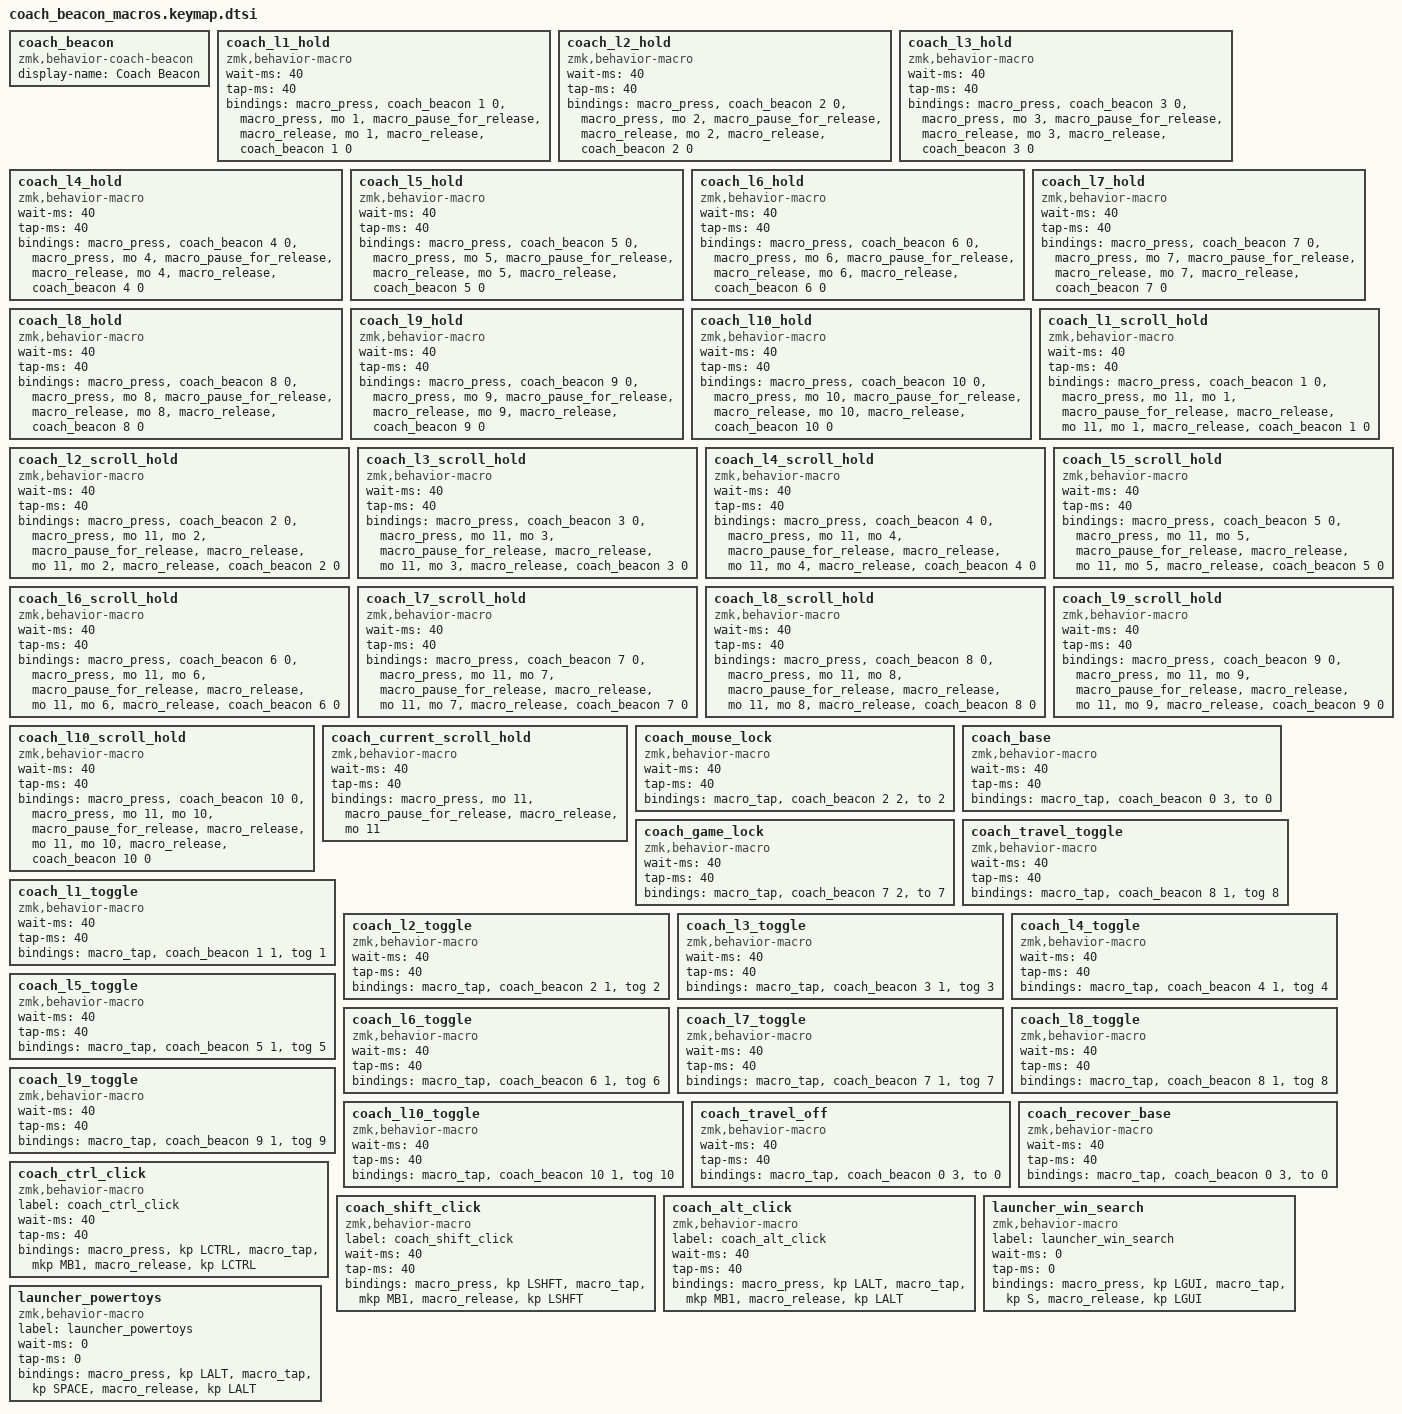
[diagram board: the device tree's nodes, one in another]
/* Coach state is sent over the private GATT service, never as keyboard input. */

coach_beacon: coach_beacon {
    compatible = "zmk,behavior-coach-beacon";
    #binding-cells = <2>;
    display-name = "Coach Beacon";
};

coach_l1_hold: coach_l1_hold {
            compatible = "zmk,behavior-macro";
            #binding-cells = <0>;
            wait-ms = <40>;
            tap-ms = <40>;
            bindings =
                <&macro_press &coach_beacon 1 0>,
                <&macro_press &mo 1>,
                <&macro_pause_for_release>,
                <&macro_release &mo 1>,
                <&macro_release &coach_beacon 1 0>;
        };

        coach_l2_hold: coach_l2_hold {
            compatible = "zmk,behavior-macro";
            #binding-cells = <0>;
            wait-ms = <40>;
            tap-ms = <40>;
            bindings =
                <&macro_press &coach_beacon 2 0>,
                <&macro_press &mo 2>,
                <&macro_pause_for_release>,
                <&macro_release &mo 2>,
                <&macro_release &coach_beacon 2 0>;
        };

        coach_l3_hold: coach_l3_hold {
            compatible = "zmk,behavior-macro";
            #binding-cells = <0>;
            wait-ms = <40>;
            tap-ms = <40>;
            bindings =
                <&macro_press &coach_beacon 3 0>,
                <&macro_press &mo 3>,
                <&macro_pause_for_release>,
                <&macro_release &mo 3>,
                <&macro_release &coach_beacon 3 0>;
        };

        coach_l4_hold: coach_l4_hold {
            compatible = "zmk,behavior-macro";
            #binding-cells = <0>;
            wait-ms = <40>;
            tap-ms = <40>;
            bindings =
                <&macro_press &coach_beacon 4 0>,
                <&macro_press &mo 4>,
                <&macro_pause_for_release>,
                <&macro_release &mo 4>,
                <&macro_release &coach_beacon 4 0>;
        };

        coach_l5_hold: coach_l5_hold {
            compatible = "zmk,behavior-macro";
            #binding-cells = <0>;
            wait-ms = <40>;
            tap-ms = <40>;
            bindings =
                <&macro_press &coach_beacon 5 0>,
                <&macro_press &mo 5>,
                <&macro_pause_for_release>,
                <&macro_release &mo 5>,
                <&macro_release &coach_beacon 5 0>;
        };

        coach_l6_hold: coach_l6_hold {
            compatible = "zmk,behavior-macro";
            #binding-cells = <0>;
            wait-ms = <40>;
            tap-ms = <40>;
            bindings =
                <&macro_press &coach_beacon 6 0>,
                <&macro_press &mo 6>,
                <&macro_pause_for_release>,
                <&macro_release &mo 6>,
                <&macro_release &coach_beacon 6 0>;
        };

        coach_l7_hold: coach_l7_hold {
            compatible = "zmk,behavior-macro";
            #binding-cells = <0>;
            wait-ms = <40>;
            tap-ms = <40>;
            bindings =
                <&macro_press &coach_beacon 7 0>,
                <&macro_press &mo 7>,
                <&macro_pause_for_release>,
                <&macro_release &mo 7>,
                <&macro_release &coach_beacon 7 0>;
        };

        coach_l8_hold: coach_l8_hold {
            compatible = "zmk,behavior-macro";
            #binding-cells = <0>;
            wait-ms = <40>;
            tap-ms = <40>;
            bindings =
                <&macro_press &coach_beacon 8 0>,
                <&macro_press &mo 8>,
                <&macro_pause_for_release>,
                <&macro_release &mo 8>,
                <&macro_release &coach_beacon 8 0>;
        };

        coach_l9_hold: coach_l9_hold {
            compatible = "zmk,behavior-macro";
            #binding-cells = <0>;
            wait-ms = <40>;
            tap-ms = <40>;
            bindings =
                <&macro_press &coach_beacon 9 0>,
                <&macro_press &mo 9>,
                <&macro_pause_for_release>,
                <&macro_release &mo 9>,
                <&macro_release &coach_beacon 9 0>;
        };

        coach_l10_hold: coach_l10_hold {
            compatible = "zmk,behavior-macro";
            #binding-cells = <0>;
            wait-ms = <40>;
            tap-ms = <40>;
            bindings =
                <&macro_press &coach_beacon 10 0>,
                <&macro_press &mo 10>,
                <&macro_pause_for_release>,
                <&macro_release &mo 10>,
                <&macro_release &coach_beacon 10 0>;
        };

        // coach_l<N>_scroll_hold: holding these activates L11 (scroll mode - see
        // scroll-layers in charybdis_right.overlay) AND layer N simultaneously, so
        // the held key's bindings show layer N's shortcuts instead of falling
        // through to whatever layer was already active. Plain "&mo 11" alone (used
        // for scroll-hold keys before this) only ever exposes the layer already
        // active underneath it - it cannot reveal a different target layer's
        // bindings. Reuses the private GATT beacon used by coach_lN_hold below,
        // so the AHK helper reports "layer N held" the
        // same way regardless of whether it was a plain hold or a scroll-hold - the
        // coach only cares that layer N is active, not which key caused it.
        coach_l1_scroll_hold: coach_l1_scroll_hold {
            compatible = "zmk,behavior-macro";
            #binding-cells = <0>;
            wait-ms = <40>;
            tap-ms = <40>;
            bindings =
                <&macro_press &coach_beacon 1 0>,
                <&macro_press &mo 11 &mo 1>,
                <&macro_pause_for_release>,
                <&macro_release &mo 11 &mo 1>,
                <&macro_release &coach_beacon 1 0>;
        };

        coach_l2_scroll_hold: coach_l2_scroll_hold {
            compatible = "zmk,behavior-macro";
            #binding-cells = <0>;
            wait-ms = <40>;
            tap-ms = <40>;
            bindings =
                <&macro_press &coach_beacon 2 0>,
                <&macro_press &mo 11 &mo 2>,
                <&macro_pause_for_release>,
                <&macro_release &mo 11 &mo 2>,
                <&macro_release &coach_beacon 2 0>;
        };

        coach_l3_scroll_hold: coach_l3_scroll_hold {
            compatible = "zmk,behavior-macro";
            #binding-cells = <0>;
            wait-ms = <40>;
            tap-ms = <40>;
            bindings =
                <&macro_press &coach_beacon 3 0>,
                <&macro_press &mo 11 &mo 3>,
                <&macro_pause_for_release>,
                <&macro_release &mo 11 &mo 3>,
                <&macro_release &coach_beacon 3 0>;
        };

        coach_l4_scroll_hold: coach_l4_scroll_hold {
            compatible = "zmk,behavior-macro";
            #binding-cells = <0>;
            wait-ms = <40>;
            tap-ms = <40>;
            bindings =
                <&macro_press &coach_beacon 4 0>,
                <&macro_press &mo 11 &mo 4>,
                <&macro_pause_for_release>,
                <&macro_release &mo 11 &mo 4>,
                <&macro_release &coach_beacon 4 0>;
        };

        coach_l5_scroll_hold: coach_l5_scroll_hold {
            compatible = "zmk,behavior-macro";
            #binding-cells = <0>;
            wait-ms = <40>;
            tap-ms = <40>;
            bindings =
                <&macro_press &coach_beacon 5 0>,
                <&macro_press &mo 11 &mo 5>,
                <&macro_pause_for_release>,
                <&macro_release &mo 11 &mo 5>,
                <&macro_release &coach_beacon 5 0>;
        };

        coach_l6_scroll_hold: coach_l6_scroll_hold {
            compatible = "zmk,behavior-macro";
            #binding-cells = <0>;
            wait-ms = <40>;
            tap-ms = <40>;
            bindings =
                <&macro_press &coach_beacon 6 0>,
                <&macro_press &mo 11 &mo 6>,
                <&macro_pause_for_release>,
                <&macro_release &mo 11 &mo 6>,
                <&macro_release &coach_beacon 6 0>;
        };

        coach_l7_scroll_hold: coach_l7_scroll_hold {
            compatible = "zmk,behavior-macro";
            #binding-cells = <0>;
            wait-ms = <40>;
            tap-ms = <40>;
            bindings =
                <&macro_press &coach_beacon 7 0>,
                <&macro_press &mo 11 &mo 7>,
                <&macro_pause_for_release>,
                <&macro_release &mo 11 &mo 7>,
                <&macro_release &coach_beacon 7 0>;
        };

        coach_l8_scroll_hold: coach_l8_scroll_hold {
            compatible = "zmk,behavior-macro";
            #binding-cells = <0>;
            wait-ms = <40>;
            tap-ms = <40>;
            bindings =
                <&macro_press &coach_beacon 8 0>,
                <&macro_press &mo 11 &mo 8>,
                <&macro_pause_for_release>,
                <&macro_release &mo 11 &mo 8>,
                <&macro_release &coach_beacon 8 0>;
        };

        coach_l9_scroll_hold: coach_l9_scroll_hold {
            compatible = "zmk,behavior-macro";
            #binding-cells = <0>;
            wait-ms = <40>;
            tap-ms = <40>;
            bindings =
                <&macro_press &coach_beacon 9 0>,
                <&macro_press &mo 11 &mo 9>,
                <&macro_pause_for_release>,
                <&macro_release &mo 11 &mo 9>,
                <&macro_release &coach_beacon 9 0>;
        };

        coach_l10_scroll_hold: coach_l10_scroll_hold {
            compatible = "zmk,behavior-macro";
            #binding-cells = <0>;
            wait-ms = <40>;
            tap-ms = <40>;
            bindings =
                <&macro_press &coach_beacon 10 0>,
                <&macro_press &mo 11 &mo 10>,
                <&macro_pause_for_release>,
                <&macro_release &mo 11 &mo 10>,
                <&macro_release &coach_beacon 10 0>;
        };

        coach_current_scroll_hold: coach_current_scroll_hold {
            compatible = "zmk,behavior-macro";
            #binding-cells = <0>;
            wait-ms = <40>;
            tap-ms = <40>;
            bindings =
                <&macro_press &mo 11>,
                <&macro_pause_for_release>,
                <&macro_release &mo 11>;
        };

        coach_mouse_lock: coach_mouse_lock {
            compatible = "zmk,behavior-macro";
            #binding-cells = <0>;
            wait-ms = <40>;
            tap-ms = <40>;
            bindings = <&macro_tap &coach_beacon 2 2>, <&to 2>;
        };

        coach_base: coach_base {
            compatible = "zmk,behavior-macro";
            #binding-cells = <0>;
            wait-ms = <40>;
            tap-ms = <40>;
            bindings = <&macro_tap &coach_beacon 0 3>, <&to 0>;
        };

        coach_game_lock: coach_game_lock {
            compatible = "zmk,behavior-macro";
            #binding-cells = <0>;
            wait-ms = <40>;
            tap-ms = <40>;
            bindings = <&macro_tap &coach_beacon 7 2>, <&to 7>;
        };

        coach_travel_toggle: coach_travel_toggle {
            compatible = "zmk,behavior-macro";
            #binding-cells = <0>;
            wait-ms = <40>;
            tap-ms = <40>;
            bindings = <&macro_tap &coach_beacon 8 1>, <&tog 8>;
        };

        coach_l1_toggle: coach_l1_toggle {
            compatible = "zmk,behavior-macro";
            #binding-cells = <0>;
            wait-ms = <40>;
            tap-ms = <40>;
            bindings = <&macro_tap &coach_beacon 1 1>, <&tog 1>;
        };

        coach_l2_toggle: coach_l2_toggle {
            compatible = "zmk,behavior-macro";
            #binding-cells = <0>;
            wait-ms = <40>;
            tap-ms = <40>;
            bindings = <&macro_tap &coach_beacon 2 1>, <&tog 2>;
        };

        coach_l3_toggle: coach_l3_toggle {
            compatible = "zmk,behavior-macro";
            #binding-cells = <0>;
            wait-ms = <40>;
            tap-ms = <40>;
            bindings = <&macro_tap &coach_beacon 3 1>, <&tog 3>;
        };

        coach_l4_toggle: coach_l4_toggle {
            compatible = "zmk,behavior-macro";
            #binding-cells = <0>;
            wait-ms = <40>;
            tap-ms = <40>;
            bindings = <&macro_tap &coach_beacon 4 1>, <&tog 4>;
        };

        coach_l5_toggle: coach_l5_toggle {
            compatible = "zmk,behavior-macro";
            #binding-cells = <0>;
            wait-ms = <40>;
            tap-ms = <40>;
            bindings = <&macro_tap &coach_beacon 5 1>, <&tog 5>;
        };

        coach_l6_toggle: coach_l6_toggle {
            compatible = "zmk,behavior-macro";
            #binding-cells = <0>;
            wait-ms = <40>;
            tap-ms = <40>;
            bindings = <&macro_tap &coach_beacon 6 1>, <&tog 6>;
        };

        coach_l7_toggle: coach_l7_toggle {
            compatible = "zmk,behavior-macro";
            #binding-cells = <0>;
            wait-ms = <40>;
            tap-ms = <40>;
            bindings = <&macro_tap &coach_beacon 7 1>, <&tog 7>;
        };

        coach_l8_toggle: coach_l8_toggle {
            compatible = "zmk,behavior-macro";
            #binding-cells = <0>;
            wait-ms = <40>;
            tap-ms = <40>;
            bindings = <&macro_tap &coach_beacon 8 1>, <&tog 8>;
        };

        coach_l9_toggle: coach_l9_toggle {
            compatible = "zmk,behavior-macro";
            #binding-cells = <0>;
            wait-ms = <40>;
            tap-ms = <40>;
            bindings = <&macro_tap &coach_beacon 9 1>, <&tog 9>;
        };

        coach_l10_toggle: coach_l10_toggle {
            compatible = "zmk,behavior-macro";
            #binding-cells = <0>;
            wait-ms = <40>;
            tap-ms = <40>;
            bindings = <&macro_tap &coach_beacon 10 1>, <&tog 10>;
        };

        coach_travel_off: coach_travel_off {
            compatible = "zmk,behavior-macro";
            #binding-cells = <0>;
            wait-ms = <40>;
            tap-ms = <40>;
            bindings = <&macro_tap &coach_beacon 0 3>, <&to 0>;
        };

        coach_recover_base: coach_recover_base {
            compatible = "zmk,behavior-macro";
            #binding-cells = <0>;
            wait-ms = <40>;
            tap-ms = <40>;
            bindings = <&macro_tap &coach_beacon 0 3>, <&to 0>;
        };

        coach_ctrl_click: coach_ctrl_click {
            compatible = "zmk,behavior-macro";
            label = "coach_ctrl_click";
            #binding-cells = <0>;
            wait-ms = <40>;
            tap-ms = <40>;
            bindings =
                <&macro_press &kp LCTRL>,
                <&macro_tap &mkp MB1>,
                <&macro_release &kp LCTRL>;
        };

        coach_shift_click: coach_shift_click {
            compatible = "zmk,behavior-macro";
            label = "coach_shift_click";
            #binding-cells = <0>;
            wait-ms = <40>;
            tap-ms = <40>;
            bindings =
                <&macro_press &kp LSHFT>,
                <&macro_tap &mkp MB1>,
                <&macro_release &kp LSHFT>;
        };

        coach_alt_click: coach_alt_click {
            compatible = "zmk,behavior-macro";
            label = "coach_alt_click";
            #binding-cells = <0>;
            wait-ms = <40>;
            tap-ms = <40>;
            bindings =
                <&macro_press &kp LALT>,
                <&macro_tap &mkp MB1>,
                <&macro_release &kp LALT>;
        };

        launcher_win_search: launcher_win_search {
            compatible = "zmk,behavior-macro";
            label = "launcher_win_search";
            #binding-cells = <0>;
            wait-ms = <0>;
            tap-ms = <0>;
            bindings = <&macro_press &kp LGUI>, <&macro_tap &kp S>, <&macro_release &kp LGUI>;
        };

        launcher_powertoys: launcher_powertoys {
            compatible = "zmk,behavior-macro";
            label = "launcher_powertoys";
            #binding-cells = <0>;
            wait-ms = <0>;
            tap-ms = <0>;
            bindings = <&macro_press &kp LALT>, <&macro_tap &kp SPACE>, <&macro_release &kp LALT>;
        };
